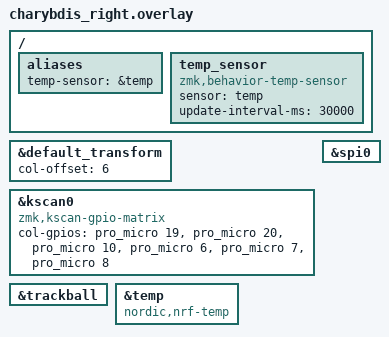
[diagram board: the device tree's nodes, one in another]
/*
 * Copyright (c) 2020 ZMK Contributors
 *
 * SPDX-License-Identifier: MIT
 */
 
#include "charybdis.dtsi"
#include "charybdis_3610.dtsi"
#include <dt-bindings/zmk/input_transform.h>

&default_transform {
	col-offset = <6>;
};


&kscan0 {
	compatible = "zmk,kscan-gpio-matrix";

	col-gpios
		= <&pro_micro 19 GPIO_ACTIVE_HIGH>
		, <&pro_micro 20 GPIO_ACTIVE_HIGH>
		, <&pro_micro 10 GPIO_ACTIVE_HIGH>
		, <&pro_micro 6 GPIO_ACTIVE_HIGH>
		, <&pro_micro 7 GPIO_ACTIVE_HIGH>
		, <&pro_micro 8 GPIO_ACTIVE_HIGH>
		;
};

&spi0 {
    status = "okay";
};

&trackball {
    status = "okay";
};

// Enable temperature sensor
&temp {
    status = "okay";
    compatible = "nordic,nrf-temp";
};

// Add temperature sensor to aliases  
/ {
    aliases {
        temp-sensor = &temp;
    };
    
    temp_sensor {
        compatible = "zmk,behavior-temp-sensor";
        sensor = <&temp>;
        update-interval-ms = <30000>; // 30 seconds
    };
};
